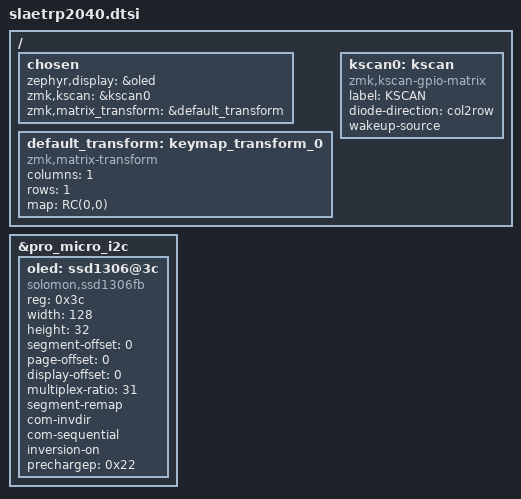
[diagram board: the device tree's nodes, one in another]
#include <dt-bindings/zmk/matrix_transform.h>


/ {
    chosen {
        zephyr,display = &oled;
        zmk,kscan = &kscan0;
        zmk,matrix_transform = &default_transform;
    };

    default_transform: keymap_transform_0 {
        compatible = "zmk,matrix-transform";
        columns = <1>;
        rows = <1>;
        map = <
            RC(0,0)
        >;
    };

    kscan0: kscan {
        compatible = "zmk,kscan-gpio-matrix";
        label = "KSCAN";

        diode-direction = "col2row";
        wakeup-source;

    };
};


&pro_micro_i2c {
    status = "okay";

    oled: ssd1306@3c {
        compatible = "solomon,ssd1306fb";
        reg = <0x3c>;
        width = <128>;
        height = <32>;
        segment-offset = <0>;
        page-offset = <0>;
        display-offset = <0>;
        multiplex-ratio = <31>;
        segment-remap;
        com-invdir;
        com-sequential;
        inversion-on;
        prechargep = <0x22>;
    };
};
